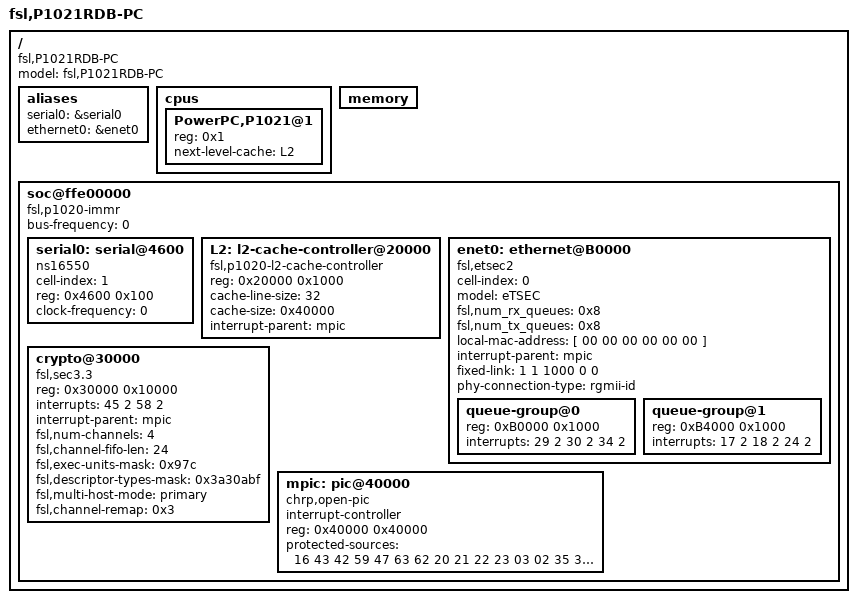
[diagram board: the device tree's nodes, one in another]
/*
 * P1021 RDB-PC Core1 Device Tree Source in CAMP mode.
 *
 * In CAMP mode, each core needs to have its own dts. Only mpic and L2 cache
 * can be shared, all the other devices must be assigned to one core only.
 * This dts allows core1 to have l2, eth0, crypto.
 *
 * Please note to add "-b 1" for core1's dts compiling.
 *
 * Copyright 2011 Freescale Semiconductor Inc.
 *
 * This program is free software; you can redistribute  it and/or modify it
 * under  the terms of  the GNU General  Public License as published by the
 * Free Software Foundation;  either version 2 of the  License, or (at your
 * option) any later version.
 */

/dts-v1/;
/ {
	model = "fsl,P1021RDB-PC";
	compatible = "fsl,P1021RDB-PC", "fsl,MPC85XXRDB-CAMP";
	#address-cells = <2>;
	#size-cells = <2>;

	aliases {
		serial0 = &serial0;
		ethernet0 = &enet0;
	};

	cpus {
		#address-cells = <1>;
		#size-cells = <0>;

		PowerPC,P1021@1 {
			device_type = "cpu";
			reg = <0x1>;
			next-level-cache = <&L2>;
		};
	};

	memory {
		device_type = "memory";
	};

	soc@ffe00000 {
		#address-cells = <1>;
		#size-cells = <1>;
		device_type = "soc";
		compatible = "fsl,p1020-immr", "simple-bus";
		ranges = <0x0  0x0 0xffe00000 0x100000>;
		bus-frequency = <0>;		// Filled out by uboot.

		serial0: serial@4600 {
			cell-index = <1>;
			device_type = "serial";
			compatible = "ns16550";
			reg = <0x4600 0x100>;
			clock-frequency = <0>;
		};

		L2: l2-cache-controller@20000 {
			compatible = "fsl,p1020-l2-cache-controller";
			reg = <0x20000 0x1000>;
			cache-line-size = <32>;	// 32 bytes
			cache-size = <0x40000>; // L2,256K
			interrupt-parent = <&mpic>;
		};

		enet0: ethernet@B0000 {
			#address-cells = <1>;
			#size-cells = <1>;
			cell-index = <0>;
			device_type = "network";
			model = "eTSEC";
			compatible = "fsl,etsec2";
			fsl,num_rx_queues = <0x8>;
			fsl,num_tx_queues = <0x8>;
			local-mac-address = [ 00 00 00 00 00 00 ];
			interrupt-parent = <&mpic>;
			fixed-link = <1 1 1000 0 0>;
			phy-connection-type = "rgmii-id";
			queue-group@0{
				#address-cells = <1>;
				#size-cells = <1>;
				reg = <0xB0000 0x1000>;
				interrupts = <29 2 30 2 34 2>;
			};
			queue-group@1{
				#address-cells = <1>;
				#size-cells = <1>;
				reg = <0xB4000 0x1000>;
				interrupts = <17 2 18 2 24 2>;
			};
		};

		crypto@30000 {
			compatible = "fsl,sec3.3", "fsl,sec3.1", "fsl,sec3.0",
				     "fsl,sec2.4", "fsl,sec2.2", "fsl,sec2.1",
				     "fsl,sec2.0";
			reg = <0x30000 0x10000>;
			interrupts = <45 2 58 2>;
			interrupt-parent = <&mpic>;
			fsl,num-channels = <4>;
			fsl,channel-fifo-len = <24>;
			fsl,exec-units-mask = <0x97c>;
			fsl,descriptor-types-mask = <0x3a30abf>;
			fsl,multi-host-mode = "primary";
			fsl,channel-remap = <0x3>;
		};

		mpic: pic@40000 {
			interrupt-controller;
			#address-cells = <0>;
			#interrupt-cells = <2>;
			reg = <0x40000 0x40000>;
			compatible = "chrp,open-pic";
			device_type = "open-pic";
			protected-sources = <
			16 		/* ecm, mem, L2, pci0, pci1 */
			43 42 59	/* i2c, serial0, spi */
			47 63 62 	/* gpio, tdm */
			20 21 22 23	/* dma */
			03 02 		/* mdio */
			35 36 40	/* enet1-queue-group0 */
			51 52 67	/* enet1-queue-group1 */
			31 32 33	/* enet2-queue-group0 */
			25 26 27	/* enet2-queue-group1 */
			28 72 58 	/* usb, sdhci, crypto */
			0xb0 0xb1 0xb2	/* message */
			0xb3 0xb4 0xb5
			0xb6 0xb7
			0xe0 0xe1 0xe2	/* msi */
			0xe3 0xe4 0xe5
			0xe6 0xe7
			>;
		};

	};

};
